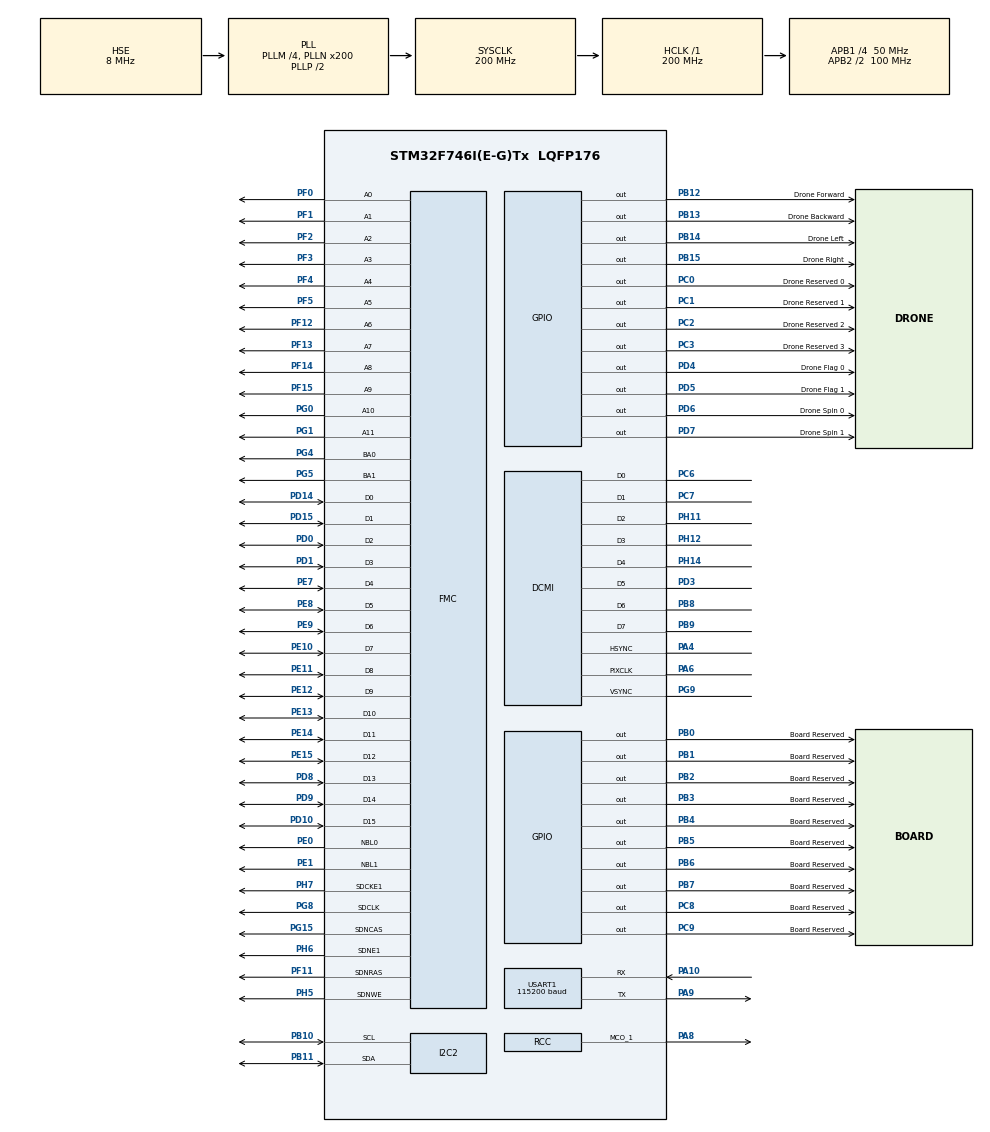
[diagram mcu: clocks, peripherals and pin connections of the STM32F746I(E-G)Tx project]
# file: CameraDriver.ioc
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DCMI.JPEGMode=DCMI_JPEG_DISABLE
DCMI.PCKPolarity=DCMI_PCKPOLARITY_RISING
Dma.DCMI.0.Direction=DMA_PERIPH_TO_MEMORY
Dma.DCMI.0.FIFOMode=DMA_FIFOMODE_ENABLE
Dma.DCMI.0.FIFOThreshold=DMA_FIFO_THRESHOLD_FULL
Dma.DCMI.0.Instance=DMA2_Stream1
Dma.DCMI.0.MemBurst=DMA_MBURST_SINGLE
Dma.DCMI.0.MemDataAlignment=DMA_MDATAALIGN_WORD
Dma.DCMI.0.MemInc=DMA_MINC_ENABLE
Dma.DCMI.0.Mode=DMA_CIRCULAR
Dma.DCMI.0.PeriphBurst=DMA_PBURST_SINGLE
Dma.DCMI.0.PeriphDataAlignment=DMA_PDATAALIGN_WORD
Dma.DCMI.0.PeriphInc=DMA_PINC_DISABLE
Dma.DCMI.0.Priority=DMA_PRIORITY_LOW
Dma.Request0=DCMI
FMC.CASLatency1=FMC_SDRAM_CAS_LATENCY_2
FMC.ExitSelfRefreshDelay1=6
FMC.LoadToActiveDelay1=2
FMC.RCDDelay1=2
FMC.RPDelay1=2
FMC.ReadBurst1=FMC_SDRAM_RBURST_ENABLE
FMC.ReadBurst2=FMC_SDRAM_RBURST_ENABLE
FMC.ReadPipeDelay1=FMC_SDRAM_RPIPE_DELAY_1
FMC.ReadPipeDelay2=FMC_SDRAM_RPIPE_DELAY_1
FMC.RowCycleDelay1=6
FMC.RowCycleDelay2=6
FMC.SDClockPeriod1=FMC_SDRAM_CLOCK_PERIOD_2
FMC.SelfRefreshTime1=4
FMC.WriteRecoveryTime1=2
I2C2.Timing=0x00C0EAFF
Mcu.Family=STM32F7
Mcu.Name=STM32F746I(E-G)Tx
Mcu.Package=LQFP176
NVIC.DCMI_IRQn=true\:0\:0\:false\:false\:true
NVIC.DMA2_Stream1_IRQn=true\:0\:0\:false\:false\:true
NVIC.PriorityGroup=NVIC_PRIORITYGROUP_4
NVIC.USART1_IRQn=true\:0\:0\:false\:false\:true
PA10.Mode=Asynchronous
PA10.Signal=USART1_RX
PA4.Mode=Slave_8_bits_External_Synchro
PA4.Signal=DCMI_HSYNC
PA6.Mode=Slave_8_bits_External_Synchro
PA6.Signal=DCMI_PIXCLK
PA8.Mode=Clock-out-1
PA8.Signal=RCC_MCO_1
PA9.Mode=Asynchronous
PA9.Signal=USART1_TX
PB0.GPIO_Label=Board Reserved
PB0.Signal=GPIO_Output
PB1.GPIO_Label=Board Reserved
PB1.Signal=GPIO_Output
PB10.Mode=I2C
PB10.Signal=I2C2_SCL
PB11.Mode=I2C
PB11.Signal=I2C2_SDA
PB12.GPIO_Label=Drone Forward
PB12.Signal=GPIO_Output
PB13.GPIO_Label=Drone Backward
PB13.Signal=GPIO_Output
PB14.GPIO_Label=Drone Left
PB14.Signal=GPIO_Output
PB15.GPIO_Label=Drone Right
PB15.Signal=GPIO_Output
PB2.GPIO_Label=Board Reserved
PB2.Signal=GPIO_Output
PB3.GPIO_Label=Board Reserved
PB3.Signal=GPIO_Output
PB4.GPIO_Label=Board Reserved
PB4.Signal=GPIO_Output
PB5.GPIO_Label=Board Reserved
PB5.Signal=GPIO_Output
PB6.GPIO_Label=Board Reserved
PB6.Signal=GPIO_Output
PB7.GPIO_Label=Board Reserved
PB7.Signal=GPIO_Output
PB8.Mode=Slave_8_bits_External_Synchro
PB8.Signal=DCMI_D6
PB9.Mode=Slave_8_bits_External_Synchro
PB9.Signal=DCMI_D7
PC0.GPIO_Label=Drone Reserved 0
PC0.Signal=GPIO_Output
PC1.GPIO_Label=Drone Reserved 1
PC1.Signal=GPIO_Output
PC2.GPIO_Label=Drone Reserved 2
PC2.Signal=GPIO_Output
PC3.GPIO_Label=Drone Reserved 3
PC3.Signal=GPIO_Output
PC6.Mode=Slave_8_bits_External_Synchro
PC6.Signal=DCMI_D0
PC7.Mode=Slave_8_bits_External_Synchro
PC7.Signal=DCMI_D1
PC8.GPIO_Label=Board Reserved
PC8.Signal=GPIO_Output
PC9.GPIO_Label=Board Reserved
PC9.Signal=GPIO_Output
PD0.GPIO_Mode=GPIO_MODE_AF_PP
PD0.GPIO_PuPd=GPIO_PULLUP
PD0.GPIO_Speed_High_Default=GPIO_SPEED_FREQ_VERY_HIGH
PD0.Signal=FMC_D2_DA2
PD1.GPIO_PuPd=GPIO_PULLUP
PD1.GPIO_Speed_High_Default=GPIO_SPEED_FREQ_VERY_HIGH
PD1.Signal=FMC_D3_DA3
PD10.GPIO_PuPd=GPIO_PULLUP
PD10.GPIO_Speed_High_Default=GPIO_SPEED_FREQ_VERY_HIGH
PD10.Signal=FMC_D15_DA15
PD14.GPIO_PuPd=GPIO_PULLUP
PD14.GPIO_Speed_High_Default=GPIO_SPEED_FREQ_VERY_HIGH
PD14.Signal=FMC_D0_DA0
PD15.GPIO_PuPd=GPIO_PULLUP
PD15.GPIO_Speed_High_Default=GPIO_SPEED_FREQ_VERY_HIGH
PD15.Signal=FMC_D1_DA1
PD3.Mode=Slave_8_bits_External_Synchro
PD3.Signal=DCMI_D5
PD4.GPIO_Label=Drone Flag 0
PD4.Signal=GPIO_Output
PD5.GPIO_Label=Drone Flag 1
PD5.Signal=GPIO_Output
PD6.GPIO_Label=Drone Spin 0
PD6.Signal=GPIO_Output
PD7.GPIO_Label=Drone Spin 1
PD7.Signal=GPIO_Output
PD8.GPIO_PuPd=GPIO_PULLUP
PD8.GPIO_Speed_High_Default=GPIO_SPEED_FREQ_VERY_HIGH
PD8.Signal=FMC_D13_DA13
PD9.GPIO_PuPd=GPIO_PULLUP
PD9.GPIO_Speed_High_Default=GPIO_SPEED_FREQ_VERY_HIGH
PD9.Signal=FMC_D14_DA14
PE0.GPIO_PuPd=GPIO_PULLUP
PE0.GPIO_Speed_High_Default=GPIO_SPEED_FREQ_VERY_HIGH
PE0.Signal=FMC_NBL0
PE1.GPIO_PuPd=GPIO_PULLUP
PE1.GPIO_Speed_High_Default=GPIO_SPEED_FREQ_VERY_HIGH
PE1.Signal=FMC_NBL1
PE10.GPIO_PuPd=GPIO_PULLUP
PE10.GPIO_Speed_High_Default=GPIO_SPEED_FREQ_VERY_HIGH
PE10.Signal=FMC_D7_DA7
PE11.GPIO_PuPd=GPIO_PULLUP
PE11.GPIO_Speed_High_Default=GPIO_SPEED_FREQ_VERY_HIGH
PE11.Signal=FMC_D8_DA8
PE12.GPIO_PuPd=GPIO_PULLUP
PE12.GPIO_Speed_High_Default=GPIO_SPEED_FREQ_VERY_HIGH
PE12.Signal=FMC_D9_DA9
PE13.GPIO_PuPd=GPIO_PULLUP
PE13.GPIO_Speed_High_Default=GPIO_SPEED_FREQ_VERY_HIGH
PE13.Signal=FMC_D10_DA10
PE14.GPIO_PuPd=GPIO_PULLUP
PE14.GPIO_Speed_High_Default=GPIO_SPEED_FREQ_VERY_HIGH
PE14.Signal=FMC_D11_DA11
PE15.GPIO_PuPd=GPIO_PULLUP
PE15.GPIO_Speed_High_Default=GPIO_SPEED_FREQ_VERY_HIGH
PE15.Signal=FMC_D12_DA12
PE7.GPIO_PuPd=GPIO_PULLUP
PE7.GPIO_Speed_High_Default=GPIO_SPEED_FREQ_VERY_HIGH
PE7.Signal=FMC_D4_DA4
PE8.GPIO_PuPd=GPIO_PULLUP
PE8.GPIO_Speed_High_Default=GPIO_SPEED_FREQ_VERY_HIGH
PE8.Signal=FMC_D5_DA5
PE9.GPIO_PuPd=GPIO_PULLUP
PE9.GPIO_Speed_High_Default=GPIO_SPEED_FREQ_VERY_HIGH
PE9.Signal=FMC_D6_DA6
PF0.GPIO_PuPd=GPIO_PULLUP
PF0.GPIO_Speed_High_Default=GPIO_SPEED_FREQ_VERY_HIGH
PF0.Signal=FMC_A0
PF1.GPIO_PuPd=GPIO_PULLUP
PF1.GPIO_Speed_High_Default=GPIO_SPEED_FREQ_VERY_HIGH
PF1.Signal=FMC_A1
PF11.GPIO_PuPd=GPIO_PULLDOWN
PF11.GPIO_Speed_High_Default=GPIO_SPEED_FREQ_VERY_HIGH
PF11.Signal=FMC_SDNRAS
PF12.GPIO_PuPd=GPIO_PULLUP
PF12.GPIO_Speed_High_Default=GPIO_SPEED_FREQ_VERY_HIGH
PF12.Signal=FMC_A6
PF13.GPIO_PuPd=GPIO_PULLUP
PF13.GPIO_Speed_High_Default=GPIO_SPEED_FREQ_VERY_HIGH
PF13.Signal=FMC_A7
PF14.GPIO_PuPd=GPIO_PULLUP
PF14.GPIO_Speed_High_Default=GPIO_SPEED_FREQ_VERY_HIGH
PF14.Signal=FMC_A8
PF15.GPIO_PuPd=GPIO_PULLUP
PF15.GPIO_Speed_High_Default=GPIO_SPEED_FREQ_VERY_HIGH
PF15.Signal=FMC_A9
PF2.GPIO_PuPd=GPIO_PULLUP
PF2.GPIO_Speed_High_Default=GPIO_SPEED_FREQ_VERY_HIGH
PF2.Signal=FMC_A2
PF3.GPIO_PuPd=GPIO_PULLUP
PF3.GPIO_Speed_High_Default=GPIO_SPEED_FREQ_VERY_HIGH
PF3.Signal=FMC_A3
PF4.GPIO_PuPd=GPIO_PULLUP
PF4.GPIO_Speed_High_Default=GPIO_SPEED_FREQ_VERY_HIGH
PF4.Signal=FMC_A4
PF5.GPIO_PuPd=GPIO_PULLUP
PF5.GPIO_Speed_High_Default=GPIO_SPEED_FREQ_VERY_HIGH
PF5.Signal=FMC_A5
PG0.GPIO_PuPd=GPIO_PULLUP
PG0.GPIO_Speed_High_Default=GPIO_SPEED_FREQ_VERY_HIGH
PG0.Signal=FMC_A10
PG1.GPIO_PuPd=GPIO_PULLUP
PG1.GPIO_Speed_High_Default=GPIO_SPEED_FREQ_VERY_HIGH
PG1.Signal=FMC_A11
PG15.GPIO_PuPd=GPIO_PULLUP
PG15.GPIO_Speed_High_Default=GPIO_SPEED_FREQ_VERY_HIGH
PG15.Signal=FMC_SDNCAS
PG4.GPIO_PuPd=GPIO_PULLUP
PG4.GPIO_Speed_High_Default=GPIO_SPEED_FREQ_VERY_HIGH
PG4.Signal=FMC_A14_BA0
PG5.GPIO_PuPd=GPIO_PULLUP
PG5.GPIO_Speed_High_Default=GPIO_SPEED_FREQ_VERY_HIGH
PG5.Signal=FMC_A15_BA1
PG8.GPIO_PuPd=GPIO_PULLUP
PG8.GPIO_Speed_High_Default=GPIO_SPEED_FREQ_VERY_HIGH
PG8.Signal=FMC_SDCLK
PG9.Mode=Slave_8_bits_External_Synchro
PG9.Signal=DCMI_VSYNC
PH0/OSC_IN.Mode=HSE-External-Oscillator
PH0/OSC_IN.Signal=RCC_OSC_IN
PH1/OSC_OUT.Mode=HSE-External-Oscillator
PH1/OSC_OUT.Signal=RCC_OSC_OUT
PH11.Mode=Slave_8_bits_External_Synchro
PH11.Signal=DCMI_D2
PH12.Mode=Slave_8_bits_External_Synchro
PH12.Signal=DCMI_D3
PH14.Mode=Slave_8_bits_External_Synchro
PH14.Signal=DCMI_D4
PH5.GPIO_PuPd=GPIO_PULLDOWN
PH5.GPIO_Speed_High_Default=GPIO_SPEED_FREQ_VERY_HIGH
PH5.Signal=FMC_SDNWE
PH6.GPIO_PuPd=GPIO_PULLDOWN
PH6.GPIO_Speed_High_Default=GPIO_SPEED_FREQ_VERY_HIGH
PH6.Mode=SdramChipSelect2_1
PH6.Signal=FMC_SDNE1
PH7.GPIO_PuPd=GPIO_PULLUP
PH7.GPIO_Speed_High_Default=GPIO_SPEED_FREQ_VERY_HIGH
PH7.Mode=SdramChipSelect2_1
PH7.Signal=FMC_SDCKE1
ProjectManager.HeapSize=0x200
ProjectManager.StackSize=0x400
ProjectManager.TargetToolchain=MDK-ARM V5
RCC.AHBFreq_Value=200000000
RCC.APB1CLKDivider=RCC_HCLK_DIV4
RCC.APB1Freq_Value=50000000
RCC.APB1TimFreq_Value=100000000
RCC.APB2CLKDivider=RCC_HCLK_DIV2
RCC.APB2Freq_Value=100000000
RCC.APB2TimFreq_Value=200000000
RCC.CortexFreq_Value=200000000
RCC.HCLKFreq_Value=200000000
RCC.HSE_VALUE=8000000
RCC.HSI_VALUE=16000000
RCC.LSE_VALUE=32768
RCC.PLLM=4
RCC.PLLN=200
RCC.PLLSourceVirtual=RCC_PLLSOURCE_HSE
RCC.SYSCLKFreq_VALUE=200000000
RCC.SYSCLKSource=RCC_SYSCLKSOURCE_PLLCLK
RCC.USBFreq_Value=200000000
RCC.VCOOutputFreq_Value=400000000
SH.FMC_A0.0=FMC_A0,12b-sda1
SH.FMC_A1.0=FMC_A1,12b-sda1
SH.FMC_A10.0=FMC_A10,12b-sda1
SH.FMC_A11.0=FMC_A11,12b-sda1
SH.FMC_A14_BA0.0=FMC_BA0,FourSdramBanks1
SH.FMC_A15_BA1.0=FMC_BA1,FourSdramBanks1
SH.FMC_A2.0=FMC_A2,12b-sda1
SH.FMC_A3.0=FMC_A3,12b-sda1
SH.FMC_A4.0=FMC_A4,12b-sda1
SH.FMC_A5.0=FMC_A5,12b-sda1
SH.FMC_A6.0=FMC_A6,12b-sda1
SH.FMC_A7.0=FMC_A7,12b-sda1
SH.FMC_A8.0=FMC_A8,12b-sda1
SH.FMC_A9.0=FMC_A9,12b-sda1
SH.FMC_D0_DA0.0=FMC_D0,sd-16b-d1
SH.FMC_D10_DA10.0=FMC_D10,sd-16b-d1
SH.FMC_D11_DA11.0=FMC_D11,sd-16b-d1
SH.FMC_D12_DA12.0=FMC_D12,sd-16b-d1
SH.FMC_D13_DA13.0=FMC_D13,sd-16b-d1
SH.FMC_D14_DA14.0=FMC_D14,sd-16b-d1
SH.FMC_D15_DA15.0=FMC_D15,sd-16b-d1
SH.FMC_D1_DA1.0=FMC_D1,sd-16b-d1
SH.FMC_D2_DA2.0=FMC_D2,sd-16b-d1
SH.FMC_D3_DA3.0=FMC_D3,sd-16b-d1
SH.FMC_D4_DA4.0=FMC_D4,sd-16b-d1
SH.FMC_D5_DA5.0=FMC_D5,sd-16b-d1
SH.FMC_D6_DA6.0=FMC_D6,sd-16b-d1
SH.FMC_D7_DA7.0=FMC_D7,sd-16b-d1
SH.FMC_D8_DA8.0=FMC_D8,sd-16b-d1
SH.FMC_D9_DA9.0=FMC_D9,sd-16b-d1
SH.FMC_NBL0.0=FMC_NBL0,Sd2ByteEnable1
SH.FMC_NBL1.0=FMC_NBL1,Sd2ByteEnable1
SH.FMC_SDCLK.0=FMC_SDCLK,12b-sda1
SH.FMC_SDNCAS.0=FMC_SDNCAS,12b-sda1
SH.FMC_SDNRAS.0=FMC_SDNRAS,12b-sda1
SH.FMC_SDNWE.0=FMC_SDNWE,12b-sda1
USART1.BaudRate=115200
USART1.DMADisableonRxErrorParam=UART_ADVFEATURE_DMA_DISABLEONRXERROR
USART1.OverrunDisableParam=UART_ADVFEATURE_OVERRUN_DISABLE
USART1.VirtualMode-Asynchronous=VM_ASYNC
USART1.WordLength=WORDLENGTH_8B
board=CameraDriver

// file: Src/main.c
/**
  ******************************************************************************
  * File Name          : main.c
  * Description        : Main program body
  ******************************************************************************
  ** This notice applies to any and all portions of this file
  * that are not between comment pairs USER CODE BEGIN and
  * USER CODE END. Other portions of this file, whether
  * inserted by the user or by software development tools
  * are owned by their respective copyright owners.
  *
  * COPYRIGHT(c) 2017 STMicroelectronics
  *
  * Redistribution and use in source and binary forms, with or without modification,
  * are permitted provided that the following conditions are met:
  *   1. Redistributions of source code must retain the above copyright notice,
  *      this list of conditions and the following disclaimer.
  *   2. Redistributions in binary form must reproduce the above copyright notice,
  *      this list of conditions and the following disclaimer in the documentation
  *      and/or other materials provided with the distribution.
  *   3. Neither the name of STMicroelectronics nor the names of its contributors
  *      may be used to endorse or promote products derived from this software
  *      without specific prior written permission.
  *
  * THIS SOFTWARE IS PROVIDED BY THE COPYRIGHT HOLDERS AND CONTRIBUTORS "AS IS"
  * AND ANY EXPRESS OR IMPLIED WARRANTIES, INCLUDING, BUT NOT LIMITED TO, THE
  * IMPLIED WARRANTIES OF MERCHANTABILITY AND FITNESS FOR A PARTICULAR PURPOSE ARE
  * DISCLAIMED. IN NO EVENT SHALL THE COPYRIGHT HOLDER OR CONTRIBUTORS BE LIABLE
  * FOR ANY DIRECT, INDIRECT, INCIDENTAL, SPECIAL, EXEMPLARY, OR CONSEQUENTIAL
  * DAMAGES (INCLUDING, BUT NOT LIMITED TO, PROCUREMENT OF SUBSTITUTE GOODS OR
  * SERVICES; LOSS OF USE, DATA, OR PROFITS; OR BUSINESS INTERRUPTION) HOWEVER
  * CAUSED AND ON ANY THEORY OF LIABILITY, WHETHER IN CONTRACT, STRICT LIABILITY,
  * OR TORT (INCLUDING NEGLIGENCE OR OTHERWISE) ARISING IN ANY WAY OUT OF THE USE
  * OF THIS SOFTWARE, EVEN IF ADVISED OF THE POSSIBILITY OF SUCH DAMAGE.
  *
  ******************************************************************************
  */
#include "main.h"
#include "stm32f7xx_hal.h"
#include "dcmi.h"
#include "dma.h"
#include "i2c.h"
#include "usart.h"
#include "gpio.h"
#include "fmc.h"

/* USER CODE BEGIN Includes */
#include "sdram.h"
#include "ov2640.h"
#include "wifi.h"
#include "image_processing.h"
/* USER CODE END Includes */

/* USER CODE BEGIN PV */
/* Private variables ---------------------------------------------------------*/

/* USER CODE END PV */

void SystemClock_Config(void);

/* USER CODE BEGIN PFP */
/* Private function prototypes -----------------------------------------------*/
static void CPU_CACHE_Enable(void);
/* USER CODE END PFP */

int main(void)
{

  /* USER CODE BEGIN 1 */

  CPU_CACHE_Enable();
  /* USER CODE END 1 */

  /* MCU Configuration----------------------------------------------------------*/

  /* Reset of all peripherals, Initializes the Flash interface and the Systick. */
  HAL_Init();

  /* Configure the system clock */
  SystemClock_Config();

  /* Initialize all configured peripherals */
  MX_GPIO_Init();
  MX_DMA_Init();
  MX_DCMI_Init();
  MX_I2C2_Init();
  MX_USART1_UART_Init();
  MX_FMC_Init();

  /* USER CODE BEGIN 2 */
  BSP_SDRAM_Initialization_sequence(REFRESH_COUNT);
  ov2640_Init(ov2640_R160x120);
  WIFI_Transparent_Init();
  ov2640_Config(OV2640_ADDR, ov2640_CONTRAST_BRIGHTNESS, OV2640_CONTRAST_LEVEL4, OV2640_BRIGHTNESS_LEVEL0);
  // ov2640_Config(OV2640_ADDR, ov2640_BLACK_WHITE, OV2640_BLACK_WHITE_BW, OV2640_BRIGHTNESS_LEVEL2);
  ov2640_SetYUV();
  ov2640_SnapshotStart(ov2640_FRAME_BUFFER);
  /* USER CODE END 2 */

  /* Infinite loop */
  while (1)
  {

    /* USER CODE BEGIN 3 */
    //    if (hdcmi.State == HAL_DCMI_STATE_SUSPENDED)
    //    {
    //      /*Process image*/
    //      Img_Process();
    //      HAL_DCMI_Resume(&hdcmi);
    //    }
  }
  /* USER CODE END 3 */
}

/** System Clock Configuration
*/
void SystemClock_Config(void)
{

  RCC_OscInitTypeDef RCC_OscInitStruct;
  RCC_ClkInitTypeDef RCC_ClkInitStruct;
  RCC_PeriphCLKInitTypeDef PeriphClkInitStruct;

  /**Configure the main internal regulator output voltage
    */
  __HAL_RCC_PWR_CLK_ENABLE();

  __HAL_PWR_VOLTAGESCALING_CONFIG(PWR_REGULATOR_VOLTAGE_SCALE1);

  /**Initializes the CPU, AHB and APB busses clocks
    */
  RCC_OscInitStruct.OscillatorType = RCC_OSCILLATORTYPE_HSI | RCC_OSCILLATORTYPE_HSE;
  RCC_OscInitStruct.HSEState = RCC_HSE_ON;
  RCC_OscInitStruct.HSIState = RCC_HSI_ON;
  RCC_OscInitStruct.HSICalibrationValue = 16;
  RCC_OscInitStruct.PLL.PLLState = RCC_PLL_ON;
  RCC_OscInitStruct.PLL.PLLSource = RCC_PLLSOURCE_HSE;
  RCC_OscInitStruct.PLL.PLLM = 4;
  RCC_OscInitStruct.PLL.PLLN = 200;
  RCC_OscInitStruct.PLL.PLLP = RCC_PLLP_DIV2;
  RCC_OscInitStruct.PLL.PLLQ = 2;
  if (HAL_RCC_OscConfig(&RCC_OscInitStruct) != HAL_OK)
  {
    _Error_Handler(__FILE__, __LINE__);
  }

  /**Activate the Over-Drive mode
    */
  if (HAL_PWREx_EnableOverDrive() != HAL_OK)
  {
    _Error_Handler(__FILE__, __LINE__);
  }

  /**Initializes the CPU, AHB and APB busses clocks
    */
  RCC_ClkInitStruct.ClockType = RCC_CLOCKTYPE_HCLK | RCC_CLOCKTYPE_SYSCLK | RCC_CLOCKTYPE_PCLK1 | RCC_CLOCKTYPE_PCLK2;
  RCC_ClkInitStruct.SYSCLKSource = RCC_SYSCLKSOURCE_PLLCLK;
  RCC_ClkInitStruct.AHBCLKDivider = RCC_SYSCLK_DIV1;
  RCC_ClkInitStruct.APB1CLKDivider = RCC_HCLK_DIV4;
  RCC_ClkInitStruct.APB2CLKDivider = RCC_HCLK_DIV2;

  if (HAL_RCC_ClockConfig(&RCC_ClkInitStruct, FLASH_LATENCY_6) != HAL_OK)
  {
    _Error_Handler(__FILE__, __LINE__);
  }

  PeriphClkInitStruct.PeriphClockSelection = RCC_PERIPHCLK_USART1 | RCC_PERIPHCLK_I2C2;
  PeriphClkInitStruct.Usart1ClockSelection = RCC_USART1CLKSOURCE_PCLK2;
  PeriphClkInitStruct.I2c2ClockSelection = RCC_I2C2CLKSOURCE_PCLK1;
  if (HAL_RCCEx_PeriphCLKConfig(&PeriphClkInitStruct) != HAL_OK)
  {
    _Error_Handler(__FILE__, __LINE__);
  }

  HAL_RCC_MCOConfig(RCC_MCO1, RCC_MCO1SOURCE_HSI, RCC_MCODIV_1);

  /**Configure the Systick interrupt time
    */
  HAL_SYSTICK_Config(HAL_RCC_GetHCLKFreq() / 1000);

  /**Configure the Systick
    */
  HAL_SYSTICK_CLKSourceConfig(SYSTICK_CLKSOURCE_HCLK);

  /* SysTick_IRQn interrupt configuration */
  HAL_NVIC_SetPriority(SysTick_IRQn, 0, 0);
}

/* USER CODE BEGIN 4 */
/**
  * @brief  CPU L1-Cache enable.
  * @param  None
  * @retval None
  */
static void CPU_CACHE_Enable(void)
{
  /* Enable I-Cache */
  SCB_EnableICache();

  /* Enable D-Cache */
  SCB_EnableDCache();
}
/* USER CODE END 4 */

void _Error_Handler(char *file, int line)
{
  while (1)
  {
  }
}

/************************ (C) COPYRIGHT STMicroelectronics *****END OF FILE****/
